# A31G33x register map
Vendor: VENDOR ABOV Semiconductor Co., Ltd.; Series: A31G33x; File version: 1.0
CPU: CM0+ r0p1, little endian, no MPU, no FPU, VTOR, 2 interrupt priority bits
Registers are 32-bit, read-only, no defined reset value unless marked. A register's access mark holds for its fields unless they carry their own. Offsets are from the block's base; [hi:lo] are bit positions.

## I2Cn
Base 0x5C000000
Same registers: I2C0 0x40004800, I2C1 0x40004900, I2C2 0x40004A00
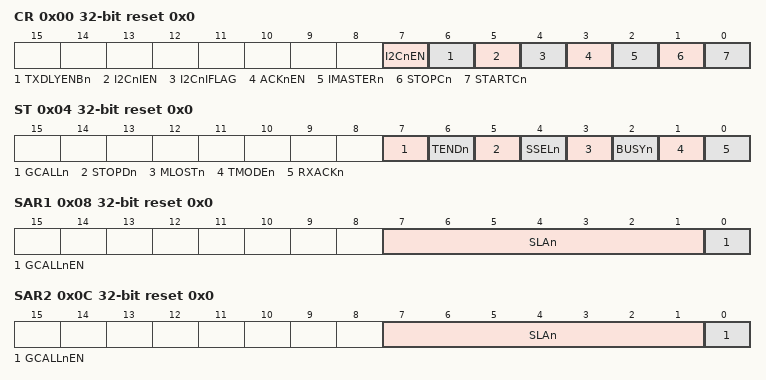
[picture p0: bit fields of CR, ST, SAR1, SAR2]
0x00 CR rw reset 0x0 — I2Cn Control Register
  [7] I2CnEN — Activate I2Cn Block by supplying
    0=Disable I2Cn block; 1=Enable I2Cn block
  [6] TXDLYENBn — I2CnSDHR Register Control
    0=Enable I2Cn_SDHR register; 1=Disable I2Cn_SDHR register
  [5] I2CnIEN — I2Cn Interrupt Enable
    0=Disable I2Cn interrupt; 1=Enable I2Cn interrupt
  [4] I2CnIFLAG — I2Cn Interrupt Flag
    0=No request occurred; 1=Request occurred
  [3] ACKnEN — Controls ACK signal generation at ninth SCL period
    0=NAK (No ACK signal is generated. (SDA = 1)); 1=ACK (ACK signal is generated. (SDA = 0))
  [2] IMASTERn ro — Represent Operation Mode of I2Cn
    0=Slave (I2Cn is in slave mode.); 1=Master (I2Cn is in master mode.)
  [1] STOPCn — STOP Condition Generation When I2Cn is master
    0=NoEffect; 1=Generate (STOP condition is to be generated.)
  [0] STARTCn — START Condition Generation When I2Cn is master
    0=NoEffect; 1=Generate (START or Repeated START condition is to be generated.)
0x04 ST rw reset 0x0 — I2Cn Status Register
  [7] GCALLn — This bit has different meaning depending on whether I2C is master or slave
    0=NoAACK_NotGCALL (No AACK is received (Master mode). General call address is not detected (Slave mode)); 1=AACK_GCALL (AACK is received (Master mode). General call address is detected (Slave mode).)
  [6] TENDn — This bit is set when 1-byte of data is transferred completely
  [5] STOPDn — This bit is set when a STOP condition is detected
  [4] SSELn — This bit is set when I2C is addressed by other master
  [3] MLOSTn — This bit represents the result of bus arbitration in master mode
  [2] BUSYn — This bit reflects bus status
  [1] TMODEn ro — This bit is used to indicate whether I2C is transmitter or receiver
  [0] RXACKn — This bit shows the state of ACK signal
0x08 SAR1 rw reset 0x0 — I2Cn Slave Address Register 1
  [7:1] SLAn — These bits configure the slave address 0 in slave mode
  [0] GCALLnEN — This bit decides whether I2Cn allows general call address 0 or not in I2Cn slave mode
0x0C SAR2 rw reset 0x0 — I2Cn Slave Address Register 2
  [7:1] SLAn — These bits configure the slave address 1 in slave mode
  [0] GCALLnEN — This bit decides whether I2Cn allows general call address 1 or not in I2Cn slave mode
0x10 DR rw reset 0x0 — I2Cn Data Register
  [7:0] DATA — The I2CnDR Transmit buffer and Receive buffer share the same I/O address with this DATA register
0x14 SDHR rw reset 0x1 — I2Cn SDA Hold Time Register
  [11:0] HLDT — This register is used to control SDA output timing from the falling edge of SCL
0x18 SCLR rw reset 0x3F — I2Cn SCL Low Period Register
  [11:0] SCLL — This register defines the low period of SCL in master mode
0x1C SCHR rw reset 0x3F — I2Cn SCL High Period Register
  [11:0] SCLH — This register defines the high period of SCL in master mode

## HSICMU — HSI clock management unit
Base 0x40006000
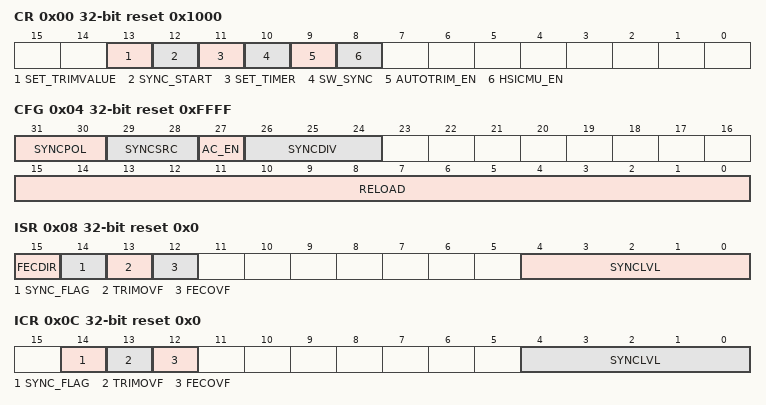
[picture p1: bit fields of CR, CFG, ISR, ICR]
0x00 CR rw reset 0x1000 — HSICMU Control Register.
  [13] SET_TRIMVALUE wo — Trim value is set to HSICMU_TRIM in HSICMU_ATRIM block.
  [12] SYNC_START — Start synchronized timer by SOF signals.
  [11] SET_TIMER wo — The value in the reload register is written to the HSICMU_TIMER counter.
  [10] SW_SYNC wo — Generate Software SYNC event.
  [9] AUTOTRIM_EN — Auto trim enable.
  [8] HSICMU_EN — HSICMU Peripheral block Enable.
0x04 CFG rw reset 0xFFFF — HSICMU Configure Register.
  [31:30] SYNCPOL — Sync Signal Polarity Selection.
  [29:28] SYNCSRC — Sync Signal Source Selection.
  [27] AC_EN — Auto Clear HSICMU_ISR.SYNC_FLAG when read HSICMU_ISR.
  [26:24] SYNCDIV — Sync Divider.
  [15:0] RELOAD — HSICMU_TIMER counter is set to RELOAD Value.
0x08 ISR reset 0x0 — HSICMU Interrupt and Status Register.
  [15] FECDIR — Frequency Error Counter Direction.
  [14] SYNC_FLAG — Sync Signal Flag.
  [13] TRIMOVF — Trim Value Overflow.
  [12] FECOVF — Frequency Error Overflow.
  [4:0] SYNCLVL — Sync Error Rate Level.
0x0C ICR rw reset 0x0 — HSICMU Interrupt and Status Clear Register.
  [14] SYNC_FLAG wo — Sync Signal Flag Clear.
  [13] TRIMOVF wo — Trim Value Overflow Flag Clear.
  [12] FECOVF wo — Frequency Error Overflow Flag Clear bit after HSICMU_CR.HSICMU_EN
  [4:0] SYNCLVL — Sync Error Rate Level Flag Clear bits after HSICMU_CR.SYNC_START set to 0.
0x10 TRIM rw reset 0x0 — HSICMU Control TRIM Value.
  [10:0] TRIM — Trim Value for Trimming.
0x14 ATRIM reset 0x0 — HSICMU Control Auto-trim Value.
  [10:0] ATRIM — Current Trim Value During Auto Trimming.
0x18 CAP reset 0x0 — HSICMU Capture Value.
  [15:0] CAPTURE — Capture Value of the Frequency Error Rate Counter.
0x1C THR rw reset 0x0 — HSICMU Frequency Error Rate Threshold.
  [15:0] FETHR — Frequency Error Rate Threshold.
